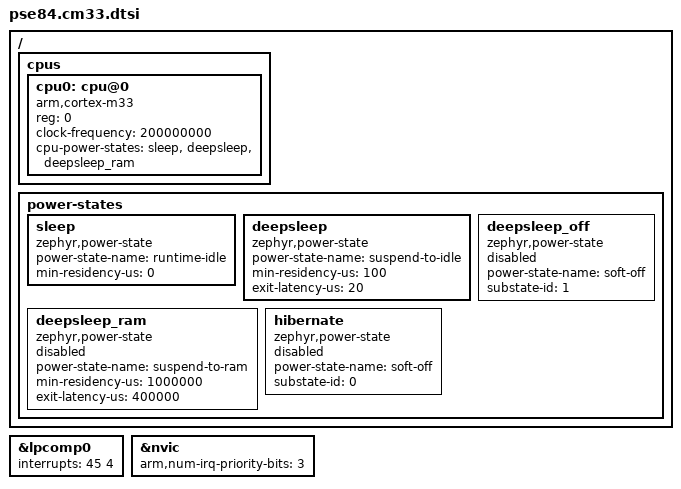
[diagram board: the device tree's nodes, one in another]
/*
 * SPDX-FileCopyrightText: Copyright (c) 2026 Infineon Technologies AG,
 * SPDX-FileCopyrightText: or an affiliate of Infineon Technologies AG. All rights reserved.
 *
 * SPDX-License-Identifier: Apache-2.0
 */

#include <arm/armv8-m.dtsi>

/ {
	cpus {
		#address-cells = <1>;
		#size-cells = <0>;

		cpu0: cpu@0 {
			device_type = "cpu";
			compatible = "arm,cortex-m33";
			reg = <0>;
			clock-frequency = <200000000>;
			cpu-power-states = <&sleep &deepsleep &deepsleep_ram>;
		};
	};

	power-states {
		sleep: sleep {
			compatible = "zephyr,power-state";
			power-state-name = "runtime-idle";
			min-residency-us = <0>;
		};

		deepsleep: deepsleep {
			compatible = "zephyr,power-state";
			power-state-name = "suspend-to-idle";
			min-residency-us = <100>;
			exit-latency-us = <20>;
		};

		/*
		 * DeepSleep-RAM is disabled by default so a plain application only
		 * sees runtime-idle and regular DeepSleep. Enabling this node
		 * turns on CONFIG_PM_S2RAM.
		 */
		deepsleep_ram: deepsleep_ram {
			compatible = "zephyr,power-state";
			power-state-name = "suspend-to-ram";
			min-residency-us = <1000000>;
			/*
			 * Warm boot resumes through the MCUboot chainload and a full
			 * Zephyr re-init, so the exit latency is dominated by that
			 * cold-boot path (measured ~381 ms; rounded up for margin)
			 * rather than the raw hardware wake time.
			 */
			exit-latency-us = <400000>;
			status = "disabled";
		};

		deepsleep_off: deepsleep_off {
			compatible = "zephyr,power-state";
			power-state-name = "soft-off";
			substate-id = <1>;
			status = "disabled";
		};

		hibernate: hibernate {
			compatible = "zephyr,power-state";
			power-state-name = "soft-off";
			substate-id = <0>;
			status = "disabled";
		};
	};
};

&lpcomp0 {
	interrupts = <45 4>;
};

&nvic {
	arm,num-irq-priority-bits = <3>;
};
